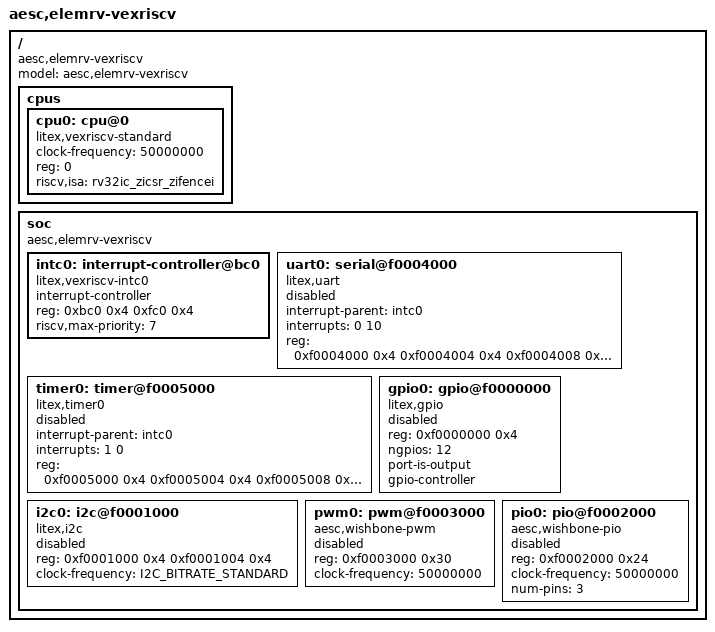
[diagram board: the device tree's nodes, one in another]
/*
 * SPDX-License-Identifier: Apache-2.0
 *
 * ElemRV-H VexRiscv SoC device tree include.
 * CPU: VexRiscv RV32IC @ 50 MHz, Wishbone bus, LiteX-compatible peripherals.
 */

#include <zephyr/dt-bindings/i2c/i2c.h>

/ {
	#address-cells = <1>;
	#size-cells = <1>;
	compatible = "aesc,elemrv-vexriscv", "litex-dev";
	model = "aesc,elemrv-vexriscv";

	cpus {
		#address-cells = <1>;
		#size-cells = <0>;
		cpu0: cpu@0 {
			clock-frequency = <50000000>;
			compatible = "litex,vexriscv-standard", "riscv";
			device_type = "cpu";
			reg = <0>;
			riscv,isa = "rv32ic_zicsr_zifencei";
			status = "okay";
		};
	};

	soc {
		#address-cells = <1>;
		#size-cells = <1>;
		compatible = "aesc,elemrv-vexriscv";
		ranges;

		intc0: interrupt-controller@bc0 {
			compatible = "litex,vexriscv-intc0";
			#address-cells = <0>;
			#interrupt-cells = <2>;
			interrupt-controller;
			reg = <0xbc0 0x4 0xfc0 0x4>;
			reg-names = "irq_mask", "irq_pending";
			riscv,max-priority = <7>;
		};

		uart0: serial@f0004000 {
			compatible = "litex,uart";
			interrupt-parent = <&intc0>;
			interrupts = <0 10>;
			reg = <0xf0004000 0x4
				0xf0004004 0x4
				0xf0004008 0x4
				0xf000400c 0x4
				0xf0004010 0x4
				0xf0004014 0x4
				0xf0004018 0x4
				0xf000401c 0x4>;
			reg-names =
				"rxtx",
				"txfull",
				"rxempty",
				"ev_status",
				"ev_pending",
				"ev_enable",
				"txempty",
				"rxfull";
			status = "disabled";
		};

		timer0: timer@f0005000 {
			compatible = "litex,timer0";
			interrupt-parent = <&intc0>;
			interrupts = <1 0>;
			reg = <0xf0005000 0x4
				0xf0005004 0x4
				0xf0005008 0x4
				0xf000500c 0x4
				0xf0005010 0x4
				0xf0005014 0x4
				0xf0005018 0x4
				0xf000501c 0x4
				0xf0005020 0x4
				0xf0005024 0x8>;
			reg-names =
				"load",
				"reload",
				"en",
				"update_value",
				"value",
				"ev_status",
				"ev_pending",
				"ev_enable",
				"uptime_latch",
				"uptime_cycles";
			status = "disabled";
		};

		gpio0: gpio@f0000000 {
			compatible = "litex,gpio";
			reg = <0xf0000000 0x4>;
			reg-names = "control";
			ngpios = <12>;
			port-is-output;
			status = "disabled";
			gpio-controller;
			#gpio-cells = <2>;
		};

		i2c0: i2c@f0001000 {
			compatible = "litex,i2c";
			reg = <0xf0001000 0x4 0xf0001004 0x4>;
			reg-names = "write", "read";
			clock-frequency = <I2C_BITRATE_STANDARD>;
			#address-cells = <1>;
			#size-cells = <0>;
			status = "disabled";
		};

		pwm0: pwm@f0003000 {
			compatible = "aesc,wishbone-pwm";
			reg = <0xf0003000 0x30>;
			#pwm-cells = <2>;
			clock-frequency = <50000000>;
			status = "disabled";
		};

		pio0: pio@f0002000 {
			compatible = "aesc,wishbone-pio";
			reg = <0xf0002000 0x24>;
			clock-frequency = <50000000>;
			num-pins = <3>;
			status = "disabled";
		};
	};
};
